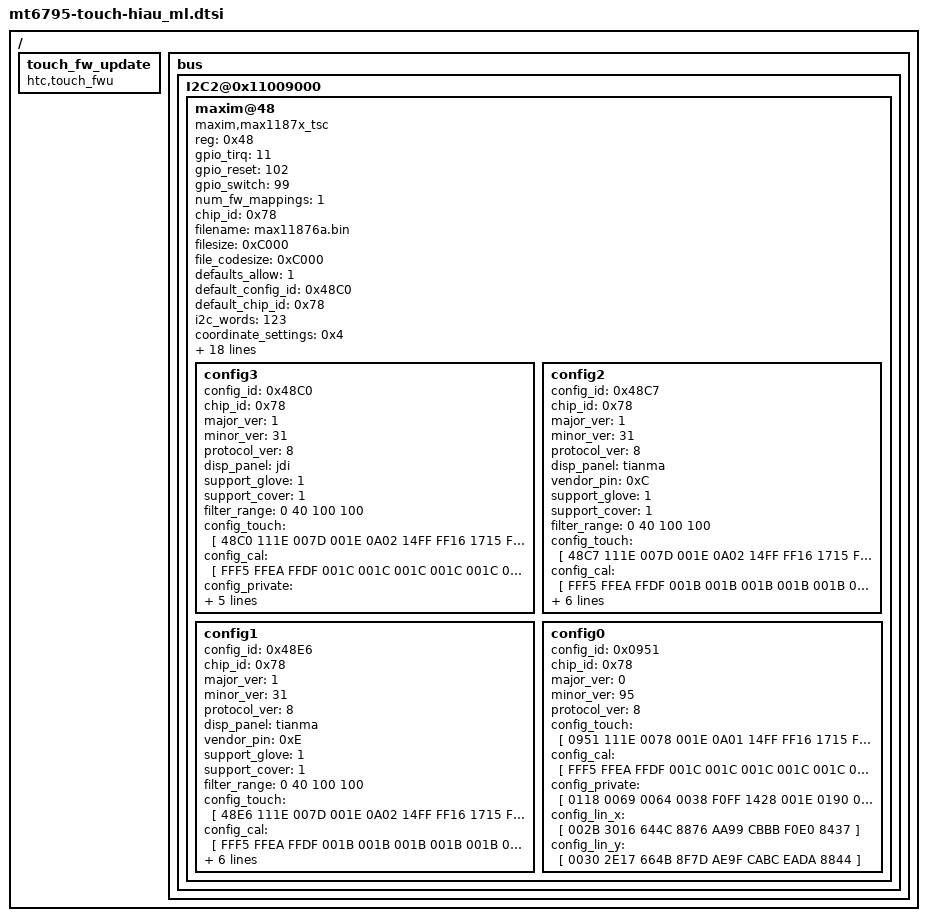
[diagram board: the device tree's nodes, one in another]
/{
	touch_fw_update {
		compatible = "htc,touch_fwu";
	};

	bus {
		I2C2@0x11009000 {
			maxim@48 {
				compatible = "maxim,max1187x_tsc";
				reg = <0x48>;
				gpio_tirq = <11>;
				gpio_reset = <102>;
				gpio_switch = <99>;
				num_fw_mappings = <1>;
				chip_id = <0x78>;
				filename = "max11876a.bin";
				filesize = <0xC000>;
				file_codesize = <0xC000>;
				defaults_allow = <1>;
				default_config_id = <0x48C0>;
				default_chip_id = <0x78>;
				i2c_words = <123>;
				coordinate_settings = <0x4>;
				panel_min_x = <0>;
				panel_max_x = <1440>;
				panel_min_y = <0>;
				panel_max_y = <2560>;
				lcd_x = <1440>;
				lcd_y = <2560>;
				num_rows = <30>;
				num_cols = <17>;
				input_protocol = <1>;
				button_code0 = <0>;
				button_code1 = <0>;
				button_code2 = <0>;
				button_code3 = <0>;
				update_feature = <2>;
				tw_mask = <0xF>;
				report_mode = <2>;
				hall_block_touch_time = <1000>;
				disp_panel_check = <1>;

				config3 {
					config_id = <0x48C0>;
					chip_id = <0x78>;
					major_ver = <1>;
					minor_ver = <31>;
					protocol_ver = <8>;
					disp_panel = "jdi";
					support_glove = <1>;
					support_cover = <1>;
					filter_range = <0 40 100 100>;
					config_touch = [
						48C0 111E 007D 001E 0A02 14FF FF16 1715
						FF1A 181B 1CFF 1D19 130F 100E 120D 0CFF
						FF11 0BFF 0AFF 0509 FF08 0703 0602 0104
						FF00 0100 0302 0504 0706 0908 0B0A 0D0C
						0F0E FF10 FFFF FFFF FFFF FFFF FFFF FFFF
						FFFF 0A00 05A0 0513 0001 0502 06CC 03B6
						0A14 05DC 00A0 0D00 0A05 FFFF FFFF FFFF
						FFFF 03E8 FFFF FFFF FFFF FFFF FFFF FFFF
						D930
					];
					config_cal = [
						FFF5 FFEA FFDF 001C 001C 001C 001C 001C
						001C 001C 001C 001C 001C 001C 001C 001C
						001C 001C 001C 001C 001C 001C 001C 001C
						001C 001C 001C 0003 0003 0003 0003 0003
						0003 0003 0003 0003 0003 0003 0003 0003
						0003 0003 0003 0003 0000 0000 0000 0000
						0000 0000 0000 FFFF FF1E 00EB 00FA 00FA
						00FA 00C8 0122 010E 00D2 00E6 000A 0001
						0001 0002 0002 0003 0001 0001 0002 0002
						0003 0A53
					];
					config_private = [
						01E0 00FA 002D 047B FB08 0028 001E 0190
						02EE 00AA 0064 0018 04E2 0096 0000 B232
						FF00 32FF FEFE FFFF 00FF FF15 4E21 0503
						7896 52BC FFFF FFFF FFFF FFFF FFFF FFFF
						FFFF 0F9D
					];
					config_lin_x = [
						003A 341C 644C 947C BAAA DACA FAEA BD7C
					];
					config_lin_y = [
						0036 321A 624A 927A B6A6 D6C6 F6E6 AB66
					];
				};

				config2 {
					config_id = <0x48C7>;
					chip_id = <0x78>;
					major_ver = <1>;
					minor_ver = <31>;
					protocol_ver = <8>;
					disp_panel = "tianma";
					vendor_pin = <0xC>;
					support_glove = <1>;
					support_cover = <1>;
					filter_range = <0 40 100 100>;
					config_touch = [
						48C7 111E 007D 001E 0A02 14FF FF16 1715
						FF1A 181B 1CFF 1D19 130F 100E 120D 0CFF
						FF11 0BFF 0AFF 0509 FF08 0703 0602 0104
						FF00 0100 0302 0504 0706 0908 0B0A 0D0C
						0F0E FF10 FFFF FFFF FFFF FFFF FFFF FFFF
						FFFF 0A00 05A0 0513 0001 0502 06A4 03B6
						0A5A 05DC 00A0 0D00 0A05 FFFF FFFF FFFF
						FFFF 03E8 FFFF FFFF FFFF FFFF FFFF FFFF
						D955
					];
					config_cal = [
						FFF5 FFEA FFDF 001B 001B 001B 001B 001B
						001B 001B 001B 001B 001B 001B 001B 001B
						001B 001B 001B 001B 001B 001B 001B 001B
						001B 001B 001B 0003 0003 0003 0003 0003
						0003 0003 0003 0003 0003 0003 0003 0003
						0003 0003 0003 0003 0000 0000 0000 0000
						0000 0000 0000 FFFF FF1E 00FA 00FA 00FA
						00FA 00C8 0122 010E 00D2 00E6 000A 0001
						0001 0002 0002 0003 0001 0001 0002 0002
						0003 0A4A
					];
					config_private = [
						01E0 00FA 002D 047B FB08 0028 001E 0190
						02EE 00AA 0064 0018 04E2 0096 0000 B232
						0000 32FF FEFE FFFF 00FF FF15 4E21 0503
						7896 52BC FFFF FFFF FFFF FFFF FFFF FFFF
						FFFF 109D
					];
					config_lin_x = [
						003A 341C 644C 947C BAAA DACA FAEA BD7C
					];
					config_lin_y = [
						003A 341C 644C 947C BAAA DACA FAEA BD7C
					];
				};

				config1 {
					config_id = <0x48E6>;
					chip_id = <0x78>;
					major_ver = <1>;
					minor_ver = <31>;
					protocol_ver = <8>;
					disp_panel = "tianma";
					vendor_pin = <0xE>;
					support_glove = <1>;
					support_cover = <1>;
					filter_range = <0 40 100 100>;
					config_touch = [
						48E6 111E 007D 001E 0A02 14FF FF16 1715
						FF1A 181B 1CFF 1D19 130F 100E 120D 0CFF
						FF11 0BFF 0AFF 0509 FF08 0703 0602 0104
						FF00 0100 0302 0504 0706 0908 0B0A 0D0C
						0F0E FF10 FFFF FFFF FFFF FFFF FFFF FFFF
						FFFF 0A00 05A0 0513 0001 0502 06A4 03B6
						0A5A 05DC 00A0 0D00 0A05 FFFF FFFF FFFF
						FFFF 03E8 FFFF FFFF FFFF FFFF FFFF FFFF
						D974
					];
					config_cal = [
						FFF5 FFEA FFDF 001B 001B 001B 001B 001B
						001B 001B 001B 001B 001B 001B 001B 001B
						001B 001B 001B 001B 001B 001B 001B 001B
						001B 001B 001B 0003 0003 0003 0003 0003
						0003 0003 0003 0003 0003 0003 0003 0003
						0003 0003 0003 0003 0000 0000 0000 0000
						0000 0000 0000 FFFF FF1E 00FA 00FA 00FA
						00FA 00C8 0122 010E 00D2 00E6 000A 0001
						0001 0002 0002 0003 0001 0001 0002 0002
						0003 0A4A
					];
					config_private = [
						01E0 00FA 002D 047B FB08 0028 001E 0190
						02EE 00AA 0064 0018 04E2 0096 0000 B232
						0000 32FF FEFE FFFF 00FF FF15 4E21 0503
						7896 52BC FFFF FFFF FFFF FFFF FFFF FFFF
						FFFF 109D
					];
					config_lin_x = [
						003A 341C 644C 947C BAAA DACA FAEA BD7C
					];
					config_lin_y = [
						003A 341C 644C 947C BAAA DACA FAEA BD7C
					];
				};

				config0 {
					config_id = <0x0951>;
					chip_id = <0x78>;
					major_ver = <0>;
					minor_ver = <95>;
					protocol_ver = <8>;
					config_touch = [
						0951 111E 0078 001E 0A01 14FF FF16 1715
						FF1A 181B 1CFF 1D19 130F 100E 120D 0CFF
						FF11 0BFF 0AFF 0509 FF08 0703 0602 0104
						FF00 0100 0302 0504 0706 0908 0B0A 0D0C
						0F0E FF10 FFFF FFFF FFFF FFFF FFFF FFFF
						FFFF 0A00 05A0 0113 0001 1902 073A 0960
						0578 04B0 0082 1900 0A08 FFFF FFFF FFFF
						FFFF 03E8 FFFF FFFF FFFF FFFF FFFF FFFF
						B5F0
					];
					config_cal = [
						FFF5 FFEA FFDF 001C 001C 001C 001C 001C
						001C 001C 001C 001C 001C 001C 001C 001C
						001C 001C 001C 001C 001C 001C 001C 001C
						001C 001C 001C 0003 0003 0003 0003 0003
						0003 0003 0003 0003 0003 0003 0003 0003
						0003 0003 0003 0003 0000 0000 0000 0000
						0000 0000 0000 FFFF FF1E 00E6 00FF 00FF
						00FF 00FF 00FF 00FF 00FF 00FF 000A 0001
						0001 0002 0002 0003 0001 0001 0002 0002
						0003 0AA8
					];
					config_private = [
						0118 0069 0064 0038 F0FF 1428 001E 0190
						03B6 00AA 0064 0018 04E2 003C 1400 B232
						FEFF FFFD FEFE FFFF 00FF FF15 4E21 0DC3
						7864 524C FFFF FFFF FFFF FFFF FFFF FFFF
						FFFF FDB8
					];
					config_lin_x = [
						002B 3016 644C 8876 AA99 CBBB F0E0 8437
					];
					config_lin_y = [
						0030 2E17 664B 8F7D AE9F CABC EADA 8844
					];
				};
			};
		};
	};
};
